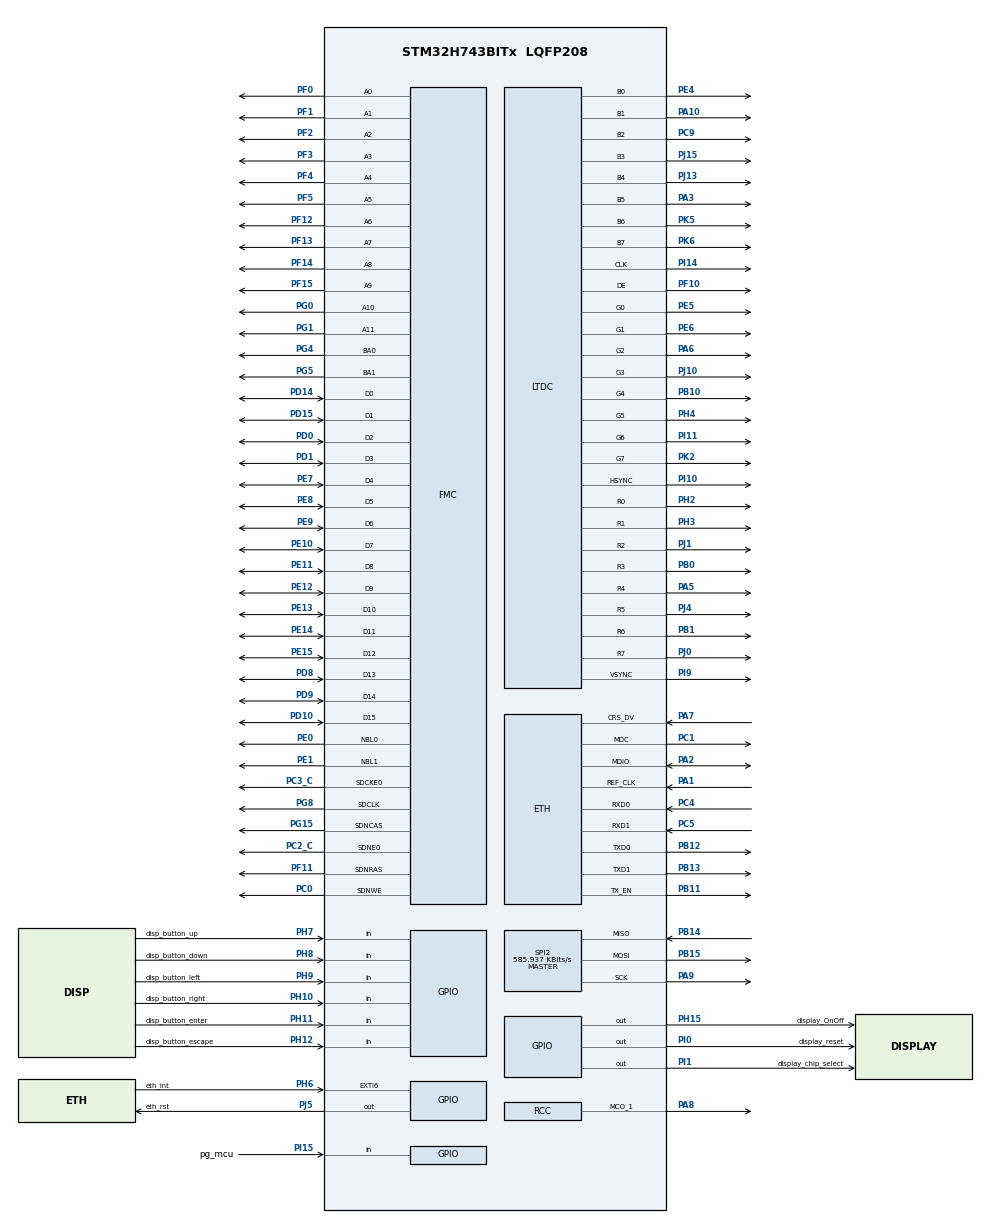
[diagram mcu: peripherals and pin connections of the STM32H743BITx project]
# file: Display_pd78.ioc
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CORTEX_M7.default_mode_Activation=0
ETH.MediaInterface=HAL_ETH_RMII_MODE
FMC.CASLatency1=FMC_SDRAM_CAS_LATENCY_3
FMC.ColumnBitsNumber1=FMC_SDRAM_COLUMN_BITS_NUM_9
FMC.ExitSelfRefreshDelay1=8
FMC.LoadToActiveDelay1=2
FMC.RCDDelay1=2
FMC.RPDelay1=2
FMC.RPDelay2=2
FMC.ReadBurst1=FMC_SDRAM_RBURST_ENABLE
FMC.ReadBurst2=FMC_SDRAM_RBURST_ENABLE
FMC.RowCycleDelay1=6
FMC.RowCycleDelay2=6
FMC.SDClockPeriod1=FMC_SDRAM_CLOCK_PERIOD_2
FMC.SDClockPeriod2=FMC_SDRAM_CLOCK_PERIOD_2
FMC.SelfRefreshTime1=4
FMC.WriteRecoveryTime1=2
FREERTOS.HEAP_NUMBER=1
FREERTOS.Queues01=input_data,1,uint16_t,0,Static,input_dataBuffer,input_dataControlBlock
FREERTOS.Tasks01=defaultTask,24,512,StartDefaultTask,Default,NULL,Static,defaultTaskBuffer,defaultTaskControlBlock;lcd_task,24,512,lcd_task_func,As external,NULL,Static,lcd_taskBuffer,lcd_taskControlBlock;HttpTask,24,1024,HttpTask_func,As external,NULL,Static,HttpTaskBuffer,HttpTaskControlBlock;button_task,24,512,button_task_func,As external,NULL,Static,button_TaskBuffer,button_TaskControlBlock;touch_task,24,512,touch_task_func,As external,NULL,Static,touch_taskBuffer,touch_taskControlBlock
FREERTOS.configCHECK_FOR_STACK_OVERFLOW=2
FREERTOS.configTOTAL_HEAP_SIZE=16384
LTDC.ActiveH=272
LTDC.ActiveW=480
LTDC.Alpha_L0=255
LTDC.FBStartAdress_L0=0xC0000000
LTDC.HBP=2
LTDC.HFP=2
LTDC.HSync=41
LTDC.ImageHeight_L0=272
LTDC.ImageWidth_L0=480
LTDC.Layers=0
LTDC.PixelFormat_L0=LTDC_PIXEL_FORMAT_RGB888
LTDC.VSync=10
LTDC.WindowX1_L0=480
LTDC.WindowY1_L0=272
LWIP.BSP.number=1
LWIP.IP_ADDRESS=192.168.100.101
LWIP.LWIP_DHCP=0
LWIP.LWIP_HTTPD=1
LWIP.LWIP_HTTPD_CGI=1
LWIP.TCP_MSS=768
LWIP.TCP_SND_BUF=2048
LWIP.TCP_WND=4048
LWIP.Version=v2.1.2_Cube
LWIP0.BSP.STBoard=false
LWIP0.BSP.api=BSP_COMPONENT_DRIVER
LWIP0.BSP.component=LAN8742
LWIP0.BSP.instance=LAN8742
LWIP0.BSP.name=Driver_PHY
LWIP0.BSP.semaphore=S_LAN8742
LWIP0.BSP.solution=LAN8742
Mcu.Family=STM32H7
Mcu.Name=STM32H743BITx
Mcu.Package=LQFP208
NVIC.ETH_IRQn=true\:5\:0\:false\:false\:true\:true\:true\:true\:true
NVIC.PriorityGroup=NVIC_PRIORITYGROUP_4
NVIC.TIM6_DAC_IRQn=true\:15\:0\:false\:false\:true\:false\:false\:true\:true
NVIC.TimeBase=TIM6_DAC_IRQn
NVIC.TimeBaseIP=TIM6
PA1.GPIO_Speed=GPIO_SPEED_FREQ_VERY_HIGH
PA1.Mode=RMII
PA1.Signal=ETH_REF_CLK
PA10.Mode=RGB888
PA10.Signal=LTDC_B1
PA2.GPIO_Speed=GPIO_SPEED_FREQ_VERY_HIGH
PA2.Mode=RMII
PA2.Signal=ETH_MDIO
PA3.Mode=RGB888
PA3.Signal=LTDC_B5
PA5.Mode=RGB888
PA5.Signal=LTDC_R4
PA6.Mode=RGB888
PA6.Signal=LTDC_G2
PA7.GPIO_Speed=GPIO_SPEED_FREQ_VERY_HIGH
PA7.Mode=RMII
PA7.Signal=ETH_CRS_DV
PA8.GPIO_Speed=GPIO_SPEED_FREQ_VERY_HIGH
PA8.Mode=Clock-out-1
PA8.Signal=RCC_MCO_1
PA9.Mode=Full_Duplex_Master
PA9.Signal=SPI2_SCK
PB0.Mode=RGB888
PB0.Signal=LTDC_R3
PB1.Mode=RGB888
PB1.Signal=LTDC_R6
PB10.Mode=RGB888
PB10.Signal=LTDC_G4
PB11.GPIO_Speed=GPIO_SPEED_FREQ_VERY_HIGH
PB11.Mode=RMII
PB11.Signal=ETH_TX_EN
PB12.GPIO_Speed=GPIO_SPEED_FREQ_VERY_HIGH
PB12.Mode=RMII
PB12.Signal=ETH_TXD0
PB13.GPIO_Speed=GPIO_SPEED_FREQ_VERY_HIGH
PB13.Mode=RMII
PB13.Signal=ETH_TXD1
PB14.Mode=Full_Duplex_Master
PB14.Signal=SPI2_MISO
PB15.Mode=Full_Duplex_Master
PB15.Signal=SPI2_MOSI
PC0.Signal=FMC_SDNWE
PC1.GPIO_Speed=GPIO_SPEED_FREQ_VERY_HIGH
PC1.Mode=RMII
PC1.Signal=ETH_MDC
PC2_C.Mode=SdramChipSelect1_1
PC2_C.Signal=FMC_SDNE0
PC3_C.Mode=SdramChipSelect1_1
PC3_C.Signal=FMC_SDCKE0
PC4.GPIO_Speed=GPIO_SPEED_FREQ_VERY_HIGH
PC4.Mode=RMII
PC4.Signal=ETH_RXD0
PC5.GPIO_Speed=GPIO_SPEED_FREQ_VERY_HIGH
PC5.Mode=RMII
PC5.Signal=ETH_RXD1
PC9.Mode=RGB888
PC9.Signal=LTDC_B2
PD0.Signal=FMC_D2_DA2
PD1.Signal=FMC_D3_DA3
PD10.Signal=FMC_D15_DA15
PD14.Signal=FMC_D0_DA0
PD15.Signal=FMC_D1_DA1
PD8.Signal=FMC_D13_DA13
PD9.Signal=FMC_D14_DA14
PE0.Signal=FMC_NBL0
PE1.Signal=FMC_NBL1
PE10.Signal=FMC_D7_DA7
PE11.Signal=FMC_D8_DA8
PE12.Signal=FMC_D9_DA9
PE13.Signal=FMC_D10_DA10
PE14.Signal=FMC_D11_DA11
PE15.Signal=FMC_D12_DA12
PE4.Mode=RGB888
PE4.Signal=LTDC_B0
PE5.Mode=RGB888
PE5.Signal=LTDC_G0
PE6.Mode=RGB888
PE6.Signal=LTDC_G1
PE7.Signal=FMC_D4_DA4
PE8.Signal=FMC_D5_DA5
PE9.Signal=FMC_D6_DA6
PF0.Signal=FMC_A0
PF1.Signal=FMC_A1
PF10.Mode=RGB888
PF10.Signal=LTDC_DE
PF11.Signal=FMC_SDNRAS
PF12.Signal=FMC_A6
PF13.Signal=FMC_A7
PF14.Signal=FMC_A8
PF15.Signal=FMC_A9
PF2.Signal=FMC_A2
PF3.Signal=FMC_A3
PF4.Signal=FMC_A4
PF5.Signal=FMC_A5
PG0.Signal=FMC_A10
PG1.Signal=FMC_A11
PG15.Signal=FMC_SDNCAS
PG4.Signal=FMC_A14_BA0
PG5.Signal=FMC_A15_BA1
PG8.Signal=FMC_SDCLK
PH0-OSC_IN\ (PH0).Mode=HSE-External-Oscillator
PH0-OSC_IN\ (PH0).Signal=RCC_OSC_IN
PH1-OSC_OUT\ (PH1).Mode=HSE-External-Oscillator
PH1-OSC_OUT\ (PH1).Signal=RCC_OSC_OUT
PH10.GPIO_Label=disp_button_right
PH10.Signal=GPIO_Input
PH11.GPIO_Label=disp_button_enter
PH11.Signal=GPIO_Input
PH12.GPIO_Label=disp_button_escape
PH12.Signal=GPIO_Input
PH15.GPIO_Label=display_OnOff
PH15.Signal=GPIO_Output
PH2.Mode=RGB888
PH2.Signal=LTDC_R0
PH3.Mode=RGB888
PH3.Signal=LTDC_R1
PH4.Mode=RGB888
PH4.Signal=LTDC_G5
PH6.GPIO_Label=eth_int
PH6.GPIO_ModeDefaultEXTI=GPIO_MODE_IT_FALLING
PH6.Signal=GPXTI6
PH7.GPIO_Label=disp_button_up
PH7.Signal=GPIO_Input
PH8.GPIO_Label=disp_button_down
PH8.Signal=GPIO_Input
PH9.GPIO_Label=disp_button_left
PH9.Signal=GPIO_Input
PI0.GPIO_Label=display_reset
PI0.Signal=GPIO_Output
PI1.GPIO_Label=display_chip_select
PI1.Signal=GPIO_Output
PI10.Mode=RGB888
PI10.Signal=LTDC_HSYNC
PI11.Mode=RGB888
PI11.Signal=LTDC_G6
PI14.Mode=RGB888
PI14.Signal=LTDC_CLK
PI15.GPIO_Label=pg_mcu
PI15.Signal=GPIO_Input
PI9.Mode=RGB888
PI9.Signal=LTDC_VSYNC
PJ0.Mode=RGB888
PJ0.Signal=LTDC_R7
PJ1.Mode=RGB888
PJ1.Signal=LTDC_R2
PJ10.Mode=RGB888
PJ10.Signal=LTDC_G3
PJ13.Mode=RGB888
PJ13.Signal=LTDC_B4
PJ15.Mode=RGB888
PJ15.Signal=LTDC_B3
PJ4.Mode=RGB888
PJ4.Signal=LTDC_R5
PJ5.GPIO_Label=eth_rst
PJ5.Signal=GPIO_Output
PK2.Mode=RGB888
PK2.Signal=LTDC_G7
PK5.Mode=RGB888
PK5.Signal=LTDC_B6
PK6.Mode=RGB888
PK6.Signal=LTDC_B7
ProjectManager.HeapSize=0x200
ProjectManager.StackSize=0x400
ProjectManager.TargetToolchain=STM32CubeIDE
RCC.ADCFreq_Value=38000000
RCC.APB1Freq_Value=75000000
RCC.APB2Freq_Value=75000000
RCC.APB3Freq_Value=75000000
RCC.APB4Freq_Value=75000000
RCC.CortexFreq_Value=300000000
RCC.D1PPRE=RCC_APB3_DIV2
RCC.D2PPRE1=RCC_APB1_DIV2
RCC.D2PPRE2=RCC_APB2_DIV2
RCC.D3PPRE=RCC_APB4_DIV2
RCC.DIVM1=1
RCC.DIVM2=1
RCC.DIVM3=1
RCC.DIVN1=75
RCC.DIVN2=19
RCC.DIVN3=45
RCC.DIVP2=4
RCC.DIVQ1=4
RCC.DIVR2=4
RCC.DIVR3=40
RCC.HCLKFreq_Value=150000000
RCC.HPRE=RCC_HCLK_DIV2
RCC.HSE_VALUE=8000000
RCC.PLL2FRACN=0
RCC.PLL3FRACN=0
RCC.PLLFRACN=0
RCC.PLLSourceVirtual=RCC_PLLSOURCE_HSE
RCC.RCC_MCO1Source=RCC_MCO1SOURCE_PLL1QCLK
RCC.RCC_MCODiv1=RCC_MCODIV_3
RCC.SYSCLKFreq_VALUE=300000000
RCC.SYSCLKSource=RCC_SYSCLKSOURCE_PLLCLK
RCC.USBFreq_Value=150000000
SH.FMC_A0.0=FMC_A0,12b-sda1
SH.FMC_A1.0=FMC_A1,12b-sda1
SH.FMC_A10.0=FMC_A10,12b-sda1
SH.FMC_A11.0=FMC_A11,12b-sda1
SH.FMC_A14_BA0.0=FMC_BA0,FourSdramBanks1
SH.FMC_A15_BA1.0=FMC_BA1,FourSdramBanks1
SH.FMC_A2.0=FMC_A2,12b-sda1
SH.FMC_A3.0=FMC_A3,12b-sda1
SH.FMC_A4.0=FMC_A4,12b-sda1
SH.FMC_A5.0=FMC_A5,12b-sda1
SH.FMC_A6.0=FMC_A6,12b-sda1
SH.FMC_A7.0=FMC_A7,12b-sda1
SH.FMC_A8.0=FMC_A8,12b-sda1
SH.FMC_A9.0=FMC_A9,12b-sda1
SH.FMC_D0_DA0.0=FMC_D0,sd-16b-d1
SH.FMC_D10_DA10.0=FMC_D10,sd-16b-d1
SH.FMC_D11_DA11.0=FMC_D11,sd-16b-d1
SH.FMC_D12_DA12.0=FMC_D12,sd-16b-d1
SH.FMC_D13_DA13.0=FMC_D13,sd-16b-d1
SH.FMC_D14_DA14.0=FMC_D14,sd-16b-d1
SH.FMC_D15_DA15.0=FMC_D15,sd-16b-d1
SH.FMC_D1_DA1.0=FMC_D1,sd-16b-d1
SH.FMC_D2_DA2.0=FMC_D2,sd-16b-d1
SH.FMC_D3_DA3.0=FMC_D3,sd-16b-d1
SH.FMC_D4_DA4.0=FMC_D4,sd-16b-d1
SH.FMC_D5_DA5.0=FMC_D5,sd-16b-d1
SH.FMC_D6_DA6.0=FMC_D6,sd-16b-d1
SH.FMC_D7_DA7.0=FMC_D7,sd-16b-d1
SH.FMC_D8_DA8.0=FMC_D8,sd-16b-d1
SH.FMC_D9_DA9.0=FMC_D9,sd-16b-d1
SH.FMC_NBL0.0=FMC_NBL0,Sd2ByteEnable1
SH.FMC_NBL1.0=FMC_NBL1,Sd2ByteEnable1
SH.FMC_SDCLK.0=FMC_SDCLK,12b-sda1
SH.FMC_SDNCAS.0=FMC_SDNCAS,12b-sda1
SH.FMC_SDNRAS.0=FMC_SDNRAS,12b-sda1
SH.FMC_SDNWE.0=FMC_SDNWE,12b-sda1
SPI2.BaudRatePrescaler=SPI_BAUDRATEPRESCALER_256
SPI2.CLKPhase=SPI_PHASE_2EDGE
SPI2.CLKPolarity=SPI_POLARITY_HIGH
SPI2.CalculateBaudRate=585.937 KBits/s
SPI2.DataSize=SPI_DATASIZE_8BIT
SPI2.Direction=SPI_DIRECTION_2LINES
SPI2.Mode=SPI_MODE_MASTER
SPI2.NSSPMode=SPI_NSS_PULSE_DISABLE
SPI2.VirtualType=VM_MASTER
VP_FREERTOS_VS_CMSIS_V2.Mode=CMSIS_V2
VP_LWIP_VS_Enabled.Mode=Enabled
VP_MEMORYMAP_VS_MEMORYMAP.Mode=CurAppReg
VP_SYS_VS_tim6.Mode=TIM6
board=custom

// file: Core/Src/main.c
/* USER CODE BEGIN Header */
/**
  ******************************************************************************
  * @file           : main.c
  * @brief          : Main program body
  ******************************************************************************
  * @attention
  *
  * Copyright (c) 2025 STMicroelectronics.
  * All rights reserved.
  *
  * This software is licensed under terms that can be found in the LICENSE file
  * in the root directory of this software component.
  * If no LICENSE file comes with this software, it is provided AS-IS.
  *
  ******************************************************************************
  */
/* USER CODE END Header */
#include "main.h"
#include "cmsis_os.h"
#include "lwip.h"

/* USER CODE BEGIN Includes */
#include "version.h"
#include "user.h"
#include "sdram.h"
/* USER CODE END Includes */

typedef StaticTask_t osStaticThreadDef_t;
typedef StaticQueue_t osStaticMessageQDef_t;

LTDC_HandleTypeDef hltdc;

SPI_HandleTypeDef hspi2;

SDRAM_HandleTypeDef hsdram1;

/* Definitions for defaultTask */
osThreadId_t defaultTaskHandle;
uint32_t defaultTaskBuffer[ 512 ];
osStaticThreadDef_t defaultTaskControlBlock;
const osThreadAttr_t defaultTask_attributes = {
  .name = "defaultTask",
  .cb_mem = &defaultTaskControlBlock,
  .cb_size = sizeof(defaultTaskControlBlock),
  .stack_mem = &defaultTaskBuffer[0],
  .stack_size = sizeof(defaultTaskBuffer),
  .priority = (osPriority_t) osPriorityNormal,
};
/* Definitions for lcd_task */
osThreadId_t lcd_taskHandle;
uint32_t lcd_taskBuffer[ 512 ];
osStaticThreadDef_t lcd_taskControlBlock;
const osThreadAttr_t lcd_task_attributes = {
  .name = "lcd_task",
  .cb_mem = &lcd_taskControlBlock,
  .cb_size = sizeof(lcd_taskControlBlock),
  .stack_mem = &lcd_taskBuffer[0],
  .stack_size = sizeof(lcd_taskBuffer),
  .priority = (osPriority_t) osPriorityNormal,
};
/* Definitions for HttpTask */
osThreadId_t HttpTaskHandle;
uint32_t HttpTaskBuffer[ 1024 ];
osStaticThreadDef_t HttpTaskControlBlock;
const osThreadAttr_t HttpTask_attributes = {
  .name = "HttpTask",
  .cb_mem = &HttpTaskControlBlock,
  .cb_size = sizeof(HttpTaskControlBlock),
  .stack_mem = &HttpTaskBuffer[0],
  .stack_size = sizeof(HttpTaskBuffer),
  .priority = (osPriority_t) osPriorityNormal,
};
/* Definitions for button_task */
osThreadId_t button_taskHandle;
uint32_t button_TaskBuffer[ 512 ];
osStaticThreadDef_t button_TaskControlBlock;
const osThreadAttr_t button_task_attributes = {
  .name = "button_task",
  .cb_mem = &button_TaskControlBlock,
  .cb_size = sizeof(button_TaskControlBlock),
  .stack_mem = &button_TaskBuffer[0],
  .stack_size = sizeof(button_TaskBuffer),
  .priority = (osPriority_t) osPriorityNormal,
};
/* Definitions for touch_task */
osThreadId_t touch_taskHandle;
uint32_t touch_taskBuffer[ 512 ];
osStaticThreadDef_t touch_taskControlBlock;
const osThreadAttr_t touch_task_attributes = {
  .name = "touch_task",
  .cb_mem = &touch_taskControlBlock,
  .cb_size = sizeof(touch_taskControlBlock),
  .stack_mem = &touch_taskBuffer[0],
  .stack_size = sizeof(touch_taskBuffer),
  .priority = (osPriority_t) osPriorityNormal,
};
/* Definitions for input_data */
osMessageQueueId_t input_dataHandle;
uint8_t input_dataBuffer[ 1 * sizeof( uint16_t ) ];
osStaticMessageQDef_t input_dataControlBlock;
const osMessageQueueAttr_t input_data_attributes = {
  .name = "input_data",
  .cb_mem = &input_dataControlBlock,
  .cb_size = sizeof(input_dataControlBlock),
  .mq_mem = &input_dataBuffer,
  .mq_size = sizeof(input_dataBuffer)
};

void SystemClock_Config(void);
static void MX_GPIO_Init(void);
static void MX_FMC_Init(void);
static void MX_LTDC_Init(void);
static void MX_SPI2_Init(void);
void StartDefaultTask(void *argument);
extern void lcd_task_func(void *argument);
extern void HttpTask_func(void *argument);
extern void button_task_func(void *argument);
extern void touch_task_func(void *argument);

int main(void)
{

  /* MCU Configuration--------------------------------------------------------*/

  /* Reset of all peripherals, Initializes the Flash interface and the Systick. */
  HAL_Init();

  /* USER CODE BEGIN Init */
  DWT_Init();
  /* USER CODE END Init */

  /* Configure the system clock */
  SystemClock_Config();

  /* Initialize all configured peripherals */
  MX_GPIO_Init();
  MX_FMC_Init();
  MX_LTDC_Init();
  MX_SPI2_Init();
  /* USER CODE BEGIN 2 */
  printf("fw ver: %s", version);
  /* USER CODE END 2 */

  /* Init scheduler */
  osKernelInitialize();

  /* Create the queue(s) */
  /* creation of input_data */
  input_dataHandle = osMessageQueueNew (1, sizeof(uint16_t), &input_data_attributes);

  /* Create the thread(s) */
  /* creation of defaultTask */
  defaultTaskHandle = osThreadNew(StartDefaultTask, NULL, &defaultTask_attributes);

  /* creation of lcd_task */
  lcd_taskHandle = osThreadNew(lcd_task_func, NULL, &lcd_task_attributes);

  /* creation of HttpTask */
  HttpTaskHandle = osThreadNew(HttpTask_func, NULL, &HttpTask_attributes);

  /* creation of button_task */
  button_taskHandle = osThreadNew(button_task_func, NULL, &button_task_attributes);

  /* creation of touch_task */
  touch_taskHandle = osThreadNew(touch_task_func, NULL, &touch_task_attributes);

  /* Start scheduler */
  osKernelStart();

  /* We should never get here as control is now taken by the scheduler */

  /* Infinite loop */
  while (1)
  {

  }
}

void SystemClock_Config(void)
{
  RCC_OscInitTypeDef RCC_OscInitStruct = {0};
  RCC_ClkInitTypeDef RCC_ClkInitStruct = {0};

  /** Supply configuration update enable
  */
  HAL_PWREx_ConfigSupply(PWR_LDO_SUPPLY);

  /** Configure the main internal regulator output voltage
  */
  __HAL_PWR_VOLTAGESCALING_CONFIG(PWR_REGULATOR_VOLTAGE_SCALE2);

  while(!__HAL_PWR_GET_FLAG(PWR_FLAG_VOSRDY)) {}

  /** Initializes the RCC Oscillators according to the specified parameters
  * in the RCC_OscInitTypeDef structure.
  */
  RCC_OscInitStruct.OscillatorType = RCC_OSCILLATORTYPE_HSE;
  RCC_OscInitStruct.HSEState = RCC_HSE_ON;
  RCC_OscInitStruct.PLL.PLLState = RCC_PLL_ON;
  RCC_OscInitStruct.PLL.PLLSource = RCC_PLLSOURCE_HSE;
  RCC_OscInitStruct.PLL.PLLM = 1;
  RCC_OscInitStruct.PLL.PLLN = 75;
  RCC_OscInitStruct.PLL.PLLP = 2;
  RCC_OscInitStruct.PLL.PLLQ = 4;
  RCC_OscInitStruct.PLL.PLLR = 2;
  RCC_OscInitStruct.PLL.PLLRGE = RCC_PLL1VCIRANGE_3;
  RCC_OscInitStruct.PLL.PLLVCOSEL = RCC_PLL1VCOWIDE;
  RCC_OscInitStruct.PLL.PLLFRACN = 0;
  if (HAL_RCC_OscConfig(&RCC_OscInitStruct) != HAL_OK)
  {
    Error_Handler();
  }

  /** Initializes the CPU, AHB and APB buses clocks
  */
  RCC_ClkInitStruct.ClockType = RCC_CLOCKTYPE_HCLK|RCC_CLOCKTYPE_SYSCLK
                              |RCC_CLOCKTYPE_PCLK1|RCC_CLOCKTYPE_PCLK2
                              |RCC_CLOCKTYPE_D3PCLK1|RCC_CLOCKTYPE_D1PCLK1;
  RCC_ClkInitStruct.SYSCLKSource = RCC_SYSCLKSOURCE_PLLCLK;
  RCC_ClkInitStruct.SYSCLKDivider = RCC_SYSCLK_DIV1;
  RCC_ClkInitStruct.AHBCLKDivider = RCC_HCLK_DIV2;
  RCC_ClkInitStruct.APB3CLKDivider = RCC_APB3_DIV2;
  RCC_ClkInitStruct.APB1CLKDivider = RCC_APB1_DIV2;
  RCC_ClkInitStruct.APB2CLKDivider = RCC_APB2_DIV2;
  RCC_ClkInitStruct.APB4CLKDivider = RCC_APB4_DIV2;

  if (HAL_RCC_ClockConfig(&RCC_ClkInitStruct, FLASH_LATENCY_2) != HAL_OK)
  {
    Error_Handler();
  }
  __HAL_RCC_PLLCLKOUT_ENABLE(RCC_PLL1_DIVQ);
  HAL_RCC_MCOConfig(RCC_MCO1, RCC_MCO1SOURCE_PLL1QCLK, RCC_MCODIV_3);
}

static void MX_LTDC_Init(void)
{

  LTDC_LayerCfgTypeDef pLayerCfg = {0};

  hltdc.Instance = LTDC;
  hltdc.Init.HSPolarity = LTDC_HSPOLARITY_AL;
  hltdc.Init.VSPolarity = LTDC_VSPOLARITY_AL;
  hltdc.Init.DEPolarity = LTDC_DEPOLARITY_AL;
  hltdc.Init.PCPolarity = LTDC_PCPOLARITY_IPC;
  hltdc.Init.HorizontalSync = 40;
  hltdc.Init.VerticalSync = 9;
  hltdc.Init.AccumulatedHBP = 42;
  hltdc.Init.AccumulatedVBP = 11;
  hltdc.Init.AccumulatedActiveW = 522;
  hltdc.Init.AccumulatedActiveH = 283;
  hltdc.Init.TotalWidth = 524;
  hltdc.Init.TotalHeigh = 285;
  hltdc.Init.Backcolor.Blue = 0;
  hltdc.Init.Backcolor.Green = 0;
  hltdc.Init.Backcolor.Red = 0;
  if (HAL_LTDC_Init(&hltdc) != HAL_OK)
  {
    Error_Handler();
  }
  pLayerCfg.WindowX0 = 0;
  pLayerCfg.WindowX1 = 480;
  pLayerCfg.WindowY0 = 0;
  pLayerCfg.WindowY1 = 272;
  pLayerCfg.PixelFormat = LTDC_PIXEL_FORMAT_RGB888;
  pLayerCfg.Alpha = 255;
  pLayerCfg.Alpha0 = 0;
  pLayerCfg.BlendingFactor1 = LTDC_BLENDING_FACTOR1_CA;
  pLayerCfg.BlendingFactor2 = LTDC_BLENDING_FACTOR2_CA;
  pLayerCfg.FBStartAdress = 0xC0000000;
  pLayerCfg.ImageWidth = 480;
  pLayerCfg.ImageHeight = 272;
  pLayerCfg.Backcolor.Blue = 0;
  pLayerCfg.Backcolor.Green = 0;
  pLayerCfg.Backcolor.Red = 0;
  if (HAL_LTDC_ConfigLayer(&hltdc, &pLayerCfg, 0) != HAL_OK)
  {
    Error_Handler();
  }

}

static void MX_SPI2_Init(void)
{

  /* SPI2 parameter configuration*/
  hspi2.Instance = SPI2;
  hspi2.Init.Mode = SPI_MODE_MASTER;
  hspi2.Init.Direction = SPI_DIRECTION_2LINES;
  hspi2.Init.DataSize = SPI_DATASIZE_8BIT;
  hspi2.Init.CLKPolarity = SPI_POLARITY_HIGH;
  hspi2.Init.CLKPhase = SPI_PHASE_2EDGE;
  hspi2.Init.NSS = SPI_NSS_SOFT;
  hspi2.Init.BaudRatePrescaler = SPI_BAUDRATEPRESCALER_256;
  hspi2.Init.FirstBit = SPI_FIRSTBIT_MSB;
  hspi2.Init.TIMode = SPI_TIMODE_DISABLE;
  hspi2.Init.CRCCalculation = SPI_CRCCALCULATION_DISABLE;
  hspi2.Init.CRCPolynomial = 0x0;
  hspi2.Init.NSSPMode = SPI_NSS_PULSE_DISABLE;
  hspi2.Init.NSSPolarity = SPI_NSS_POLARITY_LOW;
  hspi2.Init.FifoThreshold = SPI_FIFO_THRESHOLD_01DATA;
  hspi2.Init.TxCRCInitializationPattern = SPI_CRC_INITIALIZATION_ALL_ZERO_PATTERN;
  hspi2.Init.RxCRCInitializationPattern = SPI_CRC_INITIALIZATION_ALL_ZERO_PATTERN;
  hspi2.Init.MasterSSIdleness = SPI_MASTER_SS_IDLENESS_00CYCLE;
  hspi2.Init.MasterInterDataIdleness = SPI_MASTER_INTERDATA_IDLENESS_00CYCLE;
  hspi2.Init.MasterReceiverAutoSusp = SPI_MASTER_RX_AUTOSUSP_DISABLE;
  hspi2.Init.MasterKeepIOState = SPI_MASTER_KEEP_IO_STATE_DISABLE;
  hspi2.Init.IOSwap = SPI_IO_SWAP_DISABLE;
  if (HAL_SPI_Init(&hspi2) != HAL_OK)
  {
    Error_Handler();
  }

}

/* FMC initialization function */
static void MX_FMC_Init(void)
{

  FMC_SDRAM_TimingTypeDef SdramTiming = {0};

  /** Perform the SDRAM1 memory initialization sequence
  */
  hsdram1.Instance = FMC_SDRAM_DEVICE;
  /* hsdram1.Init */
  hsdram1.Init.SDBank = FMC_SDRAM_BANK1;
  hsdram1.Init.ColumnBitsNumber = FMC_SDRAM_COLUMN_BITS_NUM_9;
  hsdram1.Init.RowBitsNumber = FMC_SDRAM_ROW_BITS_NUM_12;
  hsdram1.Init.MemoryDataWidth = FMC_SDRAM_MEM_BUS_WIDTH_16;
  hsdram1.Init.InternalBankNumber = FMC_SDRAM_INTERN_BANKS_NUM_4;
  hsdram1.Init.CASLatency = FMC_SDRAM_CAS_LATENCY_3;
  hsdram1.Init.WriteProtection = FMC_SDRAM_WRITE_PROTECTION_DISABLE;
  hsdram1.Init.SDClockPeriod = FMC_SDRAM_CLOCK_PERIOD_2;
  hsdram1.Init.ReadBurst = FMC_SDRAM_RBURST_ENABLE;
  hsdram1.Init.ReadPipeDelay = FMC_SDRAM_RPIPE_DELAY_0;
  /* SdramTiming */
  SdramTiming.LoadToActiveDelay = 2;
  SdramTiming.ExitSelfRefreshDelay = 8;
  SdramTiming.SelfRefreshTime = 4;
  SdramTiming.RowCycleDelay = 6;
  SdramTiming.WriteRecoveryTime = 2;
  SdramTiming.RPDelay = 2;
  SdramTiming.RCDDelay = 2;

  if (HAL_SDRAM_Init(&hsdram1, &SdramTiming) != HAL_OK)
  {
    Error_Handler( );
  }

  /* USER CODE BEGIN FMC_Init 2 */
   user_SDRAM_Initialization_sequence(REFRESH_COUNT);
   test_sdram_basic();
  /* USER CODE END FMC_Init 2 */
}

static void MX_GPIO_Init(void)
{
  GPIO_InitTypeDef GPIO_InitStruct = {0};

  /* GPIO Ports Clock Enable */
  __HAL_RCC_GPIOE_CLK_ENABLE();
  __HAL_RCC_GPIOI_CLK_ENABLE();
  __HAL_RCC_GPIOF_CLK_ENABLE();
  __HAL_RCC_GPIOH_CLK_ENABLE();
  __HAL_RCC_GPIOC_CLK_ENABLE();
  __HAL_RCC_GPIOA_CLK_ENABLE();
  __HAL_RCC_GPIOB_CLK_ENABLE();
  __HAL_RCC_GPIOJ_CLK_ENABLE();
  __HAL_RCC_GPIOG_CLK_ENABLE();
  __HAL_RCC_GPIOD_CLK_ENABLE();
  __HAL_RCC_GPIOK_CLK_ENABLE();

  /*Configure GPIO pin Output Level */
  HAL_GPIO_WritePin(eth_rst_GPIO_Port, eth_rst_Pin, GPIO_PIN_RESET);

  /*Configure GPIO pin Output Level */
  HAL_GPIO_WritePin(display_OnOff_GPIO_Port, display_OnOff_Pin, GPIO_PIN_RESET);

  /*Configure GPIO pin Output Level */
  HAL_GPIO_WritePin(GPIOI, display_reset_Pin|display_chip_select_Pin, GPIO_PIN_RESET);

  /*Configure GPIO pin : pg_mcu_Pin */
  GPIO_InitStruct.Pin = pg_mcu_Pin;
  GPIO_InitStruct.Mode = GPIO_MODE_INPUT;
  GPIO_InitStruct.Pull = GPIO_NOPULL;
  HAL_GPIO_Init(pg_mcu_GPIO_Port, &GPIO_InitStruct);

  /*Configure GPIO pin : eth_rst_Pin */
  GPIO_InitStruct.Pin = eth_rst_Pin;
  GPIO_InitStruct.Mode = GPIO_MODE_OUTPUT_PP;
  GPIO_InitStruct.Pull = GPIO_NOPULL;
  GPIO_InitStruct.Speed = GPIO_SPEED_FREQ_LOW;
  HAL_GPIO_Init(eth_rst_GPIO_Port, &GPIO_InitStruct);

  /*Configure GPIO pin : eth_int_Pin */
  GPIO_InitStruct.Pin = eth_int_Pin;
  GPIO_InitStruct.Mode = GPIO_MODE_IT_FALLING;
  GPIO_InitStruct.Pull = GPIO_NOPULL;
  HAL_GPIO_Init(eth_int_GPIO_Port, &GPIO_InitStruct);

  /*Configure GPIO pins : disp_button_up_Pin disp_button_down_Pin disp_button_left_Pin disp_button_right_Pin
                           disp_button_enter_Pin disp_button_escape_Pin */
  GPIO_InitStruct.Pin = disp_button_up_Pin|disp_button_down_Pin|disp_button_left_Pin|disp_button_right_Pin
                          |disp_button_enter_Pin|disp_button_escape_Pin;
  GPIO_InitStruct.Mode = GPIO_MODE_INPUT;
  GPIO_InitStruct.Pull = GPIO_NOPULL;
  HAL_GPIO_Init(GPIOH, &GPIO_InitStruct);

  /*Configure GPIO pin : PA8 */
  GPIO_InitStruct.Pin = GPIO_PIN_8;
  GPIO_InitStruct.Mode = GPIO_MODE_AF_PP;
  GPIO_InitStruct.Pull = GPIO_NOPULL;
  GPIO_InitStruct.Speed = GPIO_SPEED_FREQ_VERY_HIGH;
  GPIO_InitStruct.Alternate = GPIO_AF0_MCO;
  HAL_GPIO_Init(GPIOA, &GPIO_InitStruct);

  /*Configure GPIO pin : display_OnOff_Pin */
  GPIO_InitStruct.Pin = display_OnOff_Pin;
  GPIO_InitStruct.Mode = GPIO_MODE_OUTPUT_PP;
  GPIO_InitStruct.Pull = GPIO_NOPULL;
  GPIO_InitStruct.Speed = GPIO_SPEED_FREQ_LOW;
  HAL_GPIO_Init(display_OnOff_GPIO_Port, &GPIO_InitStruct);

  /*Configure GPIO pins : display_reset_Pin display_chip_select_Pin */
  GPIO_InitStruct.Pin = display_reset_Pin|display_chip_select_Pin;
  GPIO_InitStruct.Mode = GPIO_MODE_OUTPUT_PP;
  GPIO_InitStruct.Pull = GPIO_NOPULL;
  GPIO_InitStruct.Speed = GPIO_SPEED_FREQ_LOW;
  HAL_GPIO_Init(GPIOI, &GPIO_InitStruct);

}

void StartDefaultTask(void *argument)
{
  /* init code for LWIP */
  MX_LWIP_Init();
  for(;;)
  {
    osDelay(1);
  }
}

void HAL_TIM_PeriodElapsedCallback(TIM_HandleTypeDef *htim)
{
  if (htim->Instance == TIM6)
  {
    HAL_IncTick();
  }
}

void Error_Handler(void)
{
  __disable_irq();
  while (1)
  {
  }
}
